# LPC800 register map
File version: 0.2
CPU: CM0 r0p0, little endian, no MPU, no FPU, 2 interrupt priority bits
Registers are 32-bit, read-write, reset 0x0 unless marked. A register's access mark holds for its fields unless they carry their own. Offsets are from the block's base; [hi:lo] are bit positions.

## SWM — Switch matrix (SWM)
Base 0x4000C000
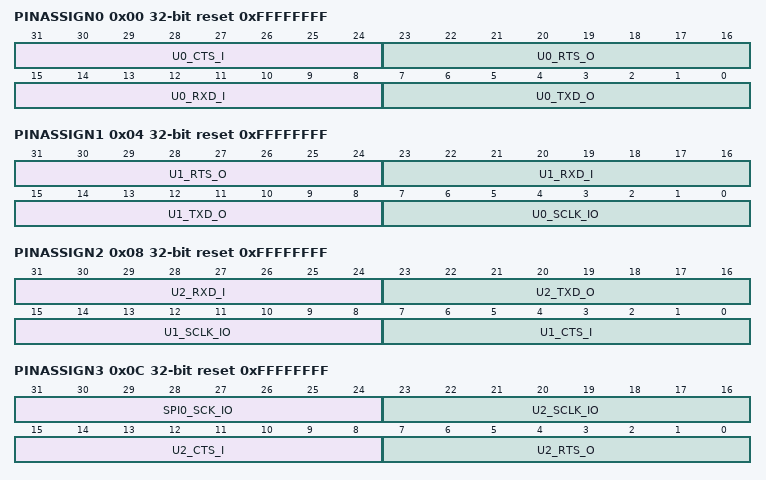
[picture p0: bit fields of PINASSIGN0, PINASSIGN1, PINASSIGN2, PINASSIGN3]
0x00 PINASSIGN0 reset 0xFFFFFFFF — Pin assign register 0. Assign movable functions U0_TXD, U0_RXD, U0_RTS, U0_CTS
  [31:24] U0_CTS_I — U0_CTS function assignment. The value is the pin number to be assigned to this function. The following pins are available: PIO0_0 (= 0) to PIO0_17 (= 0x11).
  [23:16] U0_RTS_O — U0_RTS function assignment. The value is the pin number to be assigned to this function. The following pins are available: PIO0_0 (= 0) to PIO0_17 (= 0x11).
  [15:8] U0_RXD_I — U0_RXD function assignment. The value is the pin number to be assigned to this function. The following pins are available: PIO0_0 (= 0) to PIO0_17 (= 0x11).
  [7:0] U0_TXD_O — U0_TXD function assignment. The value is the pin number to be assigned to this function. The following pins are available: PIO0_0 (= 0) to PIO0_17 (= 0x11).
0x04 PINASSIGN1 reset 0xFFFFFFFF — Pin assign register 1. Assign movable functions U0_SCLC, U1_TXD, U1_RXD
  [31:24] U1_RTS_O — U1_RTS function assignment. The value is the pin number to be assigned to this function. The following pins are available: PIO0_0 (= 0) to PIO0_17 (= 0x11).
  [23:16] U1_RXD_I — U1_RXD function assignment. The value is the pin number to be assigned to this function. The following pins are available: PIO0_0 (= 0) to PIO0_17 (= 0x11).
  [15:8] U1_TXD_O — U1_TXD function assignment. The value is the pin number to be assigned to this function. The following pins are available: PIO0_0 (= 0) to PIO0_17 (= 0x11).
  [7:0] U0_SCLK_IO — U0_SCLK function assignment. The value is the pin number to be assigned to this function. The following pins are available: PIO0_0 (= 0) to PIO0_17 (= 0x11).
0x08 PINASSIGN2 reset 0xFFFFFFFF — Pin assign register 2. Assign movable functions U2_TXD, U2_RXD
  [31:24] U2_RXD_I — U2_RXD function assignment. The value is the pin number to be assigned to this function. The following pins are available: PIO0_0 (= 0) to PIO0_17 (= 0x11).
  [23:16] U2_TXD_O — U2_TXD function assignment. The value is the pin number to be assigned to this function. The following pins are available: PIO0_0 (= 0) to PIO0_17 (= 0x11).
  [15:8] U1_SCLK_IO — U1_SCLK function assignment. The value is the pin number to be assigned to this function. The following pins are available: PIO0_0 (= 0) to PIO0_17 (= 0x11).
  [7:0] U1_CTS_I — U1_CTS function assignment. The value is the pin number to be assigned to this function. The following pins are available: PIO0_0 (= 0) to PIO0_17 (= 0x11).
0x0C PINASSIGN3 reset 0xFFFFFFFF — Pin assignregister 3. Assign movable function SPI0_SCK
  [31:24] SPI0_SCK_IO — SPI0_SCK function assignment. The value is the pin number to be assigned to this function. The following pins are available: PIO0_0 (= 0) to PIO0_17 (= 0x11).
  [23:16] U2_SCLK_IO — U2_SCLK function assignment. The value is the pin number to be assigned to this function. The following pins are available: PIO0_0 (= 0) to PIO0_17 (= 0x11).
  [15:8] U2_CTS_I — U2_CTS function assignment. The value is the pin number to be assigned to this function. The following pins are available: PIO0_0 (= 0) to PIO0_17 (= 0x11).
  [7:0] U2_RTS_O — U2_RTS function assignment. The value is the pin number to be assigned to this function. The following pins are available: PIO0_0 (= 0) to PIO0_17 (= 0x11).
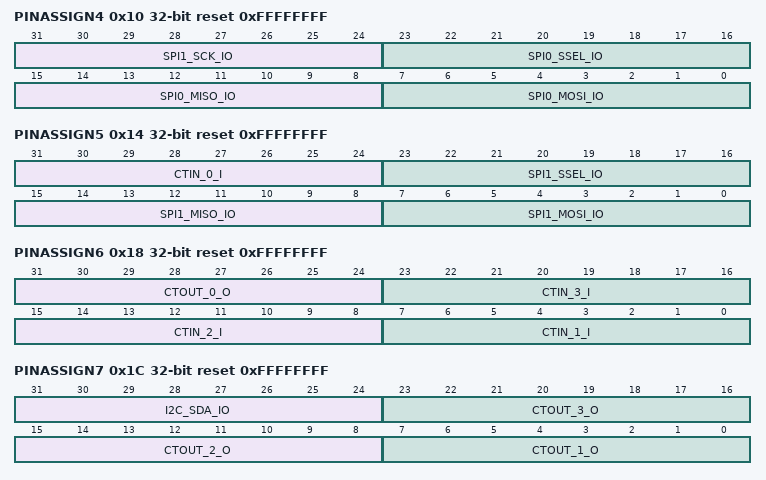
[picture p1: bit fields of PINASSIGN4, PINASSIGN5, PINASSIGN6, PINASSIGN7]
0x10 PINASSIGN4 reset 0xFFFFFFFF — Pin assign register 4. Assign movable functions SPI0_MOSI, SPI0_MISO, SPI0_SSEL, SPI1_SCK
  [31:24] SPI1_SCK_IO — SPI1_SCK function assignment. The value is the pin number to be assigned to this function. The following pins are available: PIO0_0 (= 0) to PIO0_17 (= 0x11).
  [23:16] SPI0_SSEL_IO — SPI0_SSEL function assignment. The value is the pin number to be assigned to this function. The following pins are available: PIO0_0 (= 0) to PIO0_17 (= 0x11).
  [15:8] SPI0_MISO_IO — SPI0_MISIO function assignment. The value is the pin number to be assigned to this function. The following pins are available: PIO0_0 (= 0) to PIO0_17 (= 0x11).
  [7:0] SPI0_MOSI_IO — SPI0_MOSI function assignment. The value is the pin number to be assigned to this function. The following pins are available: PIO0_0 (= 0) to PIO0_17 (= 0x11).
0x14 PINASSIGN5 reset 0xFFFFFFFF — Pin assign register 5. Assign movable functions SPI1_MOSI, SPI1_MISO, SPI1_SSEL, CTIN_0
  [31:24] CTIN_0_I — CTIN_0 function assignment. The value is the pin number to be assigned to this function. The following pins are available: PIO0_0 (= 0) to PIO0_17 (= 0x11).
  [23:16] SPI1_SSEL_IO — SPI1_SSEL function assignment. The value is the pin number to be assigned to this function. The following pins are available: PIO0_0 (= 0) to PIO0_17 (= 0x11).
  [15:8] SPI1_MISO_IO — SPI1_MISIO function assignment. The value is the pin number to be assigned to this function. The following pins are available: PIO0_0 (= 0) to PIO0_17 (= 0x11).
  [7:0] SPI1_MOSI_IO — SPI1_MOSI function assignment. The value is the pin number to be assigned to this function. The following pins are available: PIO0_0 (= 0) to PIO0_17 (= 0x11).
0x18 PINASSIGN6 reset 0xFFFFFFFF — Pin assign register 6. Assign movable functions CTIN_1, CTIN_2, CTIN_3, CTOUT_0
  [31:24] CTOUT_0_O — CTOUT_0 function assignment. The value is the pin number to be assigned to this function. The following pins are available: PIO0_0 (= 0) to PIO0_17 (= 0x11).
  [23:16] CTIN_3_I — CTIN_3 function assignment. The value is the pin number to be assigned to this function. The following pins are available: PIO0_0 (= 0) to PIO0_17 (= 0x11).
  [15:8] CTIN_2_I — CTIN_2function assignment. The value is the pin number to be assigned to this function. The following pins are available: PIO0_0 (= 0) to PIO0_17 (= 0x11).
  [7:0] CTIN_1_I — CTIN_1 function assignment. The value is the pin number to be assigned to this function. The following pins are available: PIO0_0 (= 0) to PIO0_17 (= 0x11).
0x1C PINASSIGN7 reset 0xFFFFFFFF — Pin assign egister 7. Assign movable functions CTOUT_1, CTOUT_2, CTOUT_3, I2C_SDA
  [31:24] I2C_SDA_IO — I2C_SDA function assignment. The value is the pin number to be assigned to this function. The following pins are available: PIO0_0 (= 0) to PIO0_17 (= 0x11).
  [23:16] CTOUT_3_O — CTOUT_3 function assignment. The value is the pin number to be assigned to this function. The following pins are available: PIO0_0 (= 0) to PIO0_17 (= 0x11).
  [15:8] CTOUT_2_O — CTOUT_2 function assignment. The value is the pin number to be assigned to this function. The following pins are available: PIO0_0 (= 0) to PIO0_17 (= 0x11).
  [7:0] CTOUT_1_O — CTOUT_1 function assignment. The value is the pin number to be assigned to this function. The following pins are available: PIO0_0 (= 0) to PIO0_17 (= 0x11).
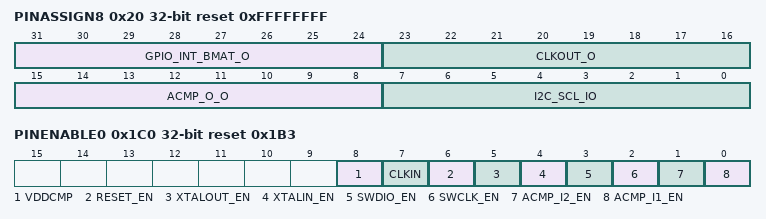
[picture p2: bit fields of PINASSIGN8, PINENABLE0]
0x20 PINASSIGN8 reset 0xFFFFFFFF — Pin assign register 8. Assign movable functions I2C_SCL, ACMP_O, CLKOUT, GPIO_INT_BMAT
  [31:24] GPIO_INT_BMAT_O — GPIO_INT_BMAT function assignment. The value is the pin number to be assigned to this function. The following pins are available: PIO0_0 (= 0) to PIO0_17 (= 0x11).
  [23:16] CLKOUT_O — CLKOUT function assignment. The value is the pin number to be assigned to this function. The following pins are available: PIO0_0 (= 0) to PIO0_17 (= 0x11).
  [15:8] ACMP_O_O — ACMP_O_O function assignment. The value is the pin number to be assigned to this function. The following pins are available: PIO0_0 (= 0) to PIO0_17 (= 0x11).
  [7:0] I2C_SCL_IO — I2C_SCL function assignment. The value is the pin number to be assigned to this function. The following pins are available: PIO0_0 (= 0) to PIO0_17 (= 0x11).
0x1C0 PINENABLE0 reset 0x1B3 — Pin enable register 0. Enables fixed-pin functions ACMP_I0, ACMP_I1, SWCLK, SWDIO, XTALIN, XTALOUT, RESET, CLKIN, VDDCMP
  [8] VDDCMP — Enables fixed-pin function. Writing a 1 deselects the function and any movable function can be assigned to this pin. By default the fixed--pin function is deselected and GPIO is assigned to this pin.
    0=ENABLE_VDDCMP_THIS_ (Enable VDDCMP. This function is enabled on pin PIO0_6.); 1=DISABLE_VDDCMP_GPIO (Disable VDDCMP. GPIO function PIO0_6 (default) or any other movable function can be assigned to pin PIO0_6.)
  [7] CLKIN — Enables fixed-pin function. Writing a 1 deselects the function and any movable function can be assigned to this pin. By default the fixed-pin function is deselected and GPIO is assigned to this pin. Functions CLKIN and ACMP_I2 are connected to the same pin PIO0_1. To use CLKIN, disable ACMP_I2 in bit 1 of this register and enable CLKIN.
    0=ENABLE_CLKIN_THIS_F (Enable CLKIN. This function is enabled on pin PIO0_1.); 1=DISABLE_CLKIN_GPIO_ (Disable CLKIN. GPIO function PIO0_1 (default) or any other movable function can be assigned to pin CLKIN.)
  [6] RESET_EN — Enables fixed-pin function. Writing a 1 deselects the function and any movable function can be assigned to this pin. This function is selected by default.
    0=ENABLE_RESET_THIS_F (Enable RESET. This function is enabled on pin PIO0_5.); 1=DISABLE_RESET_GPIO_ (Disable RESET. GPIO function PIO0_5 is selected on this pin. Any other movable function can be assigned to pin PIO0_5.)
  [5] XTALOUT_EN — Enables fixed-pin function. Writing a 1 deselects the function and any movable function can be assigned to this pin. By default the fixed--pin function is deselected and GPIO is assigned to this pin.
    0=ENABLE_XTALOUT_THIS (Enable XTALOUT. This function is enabled on pin PIO0_9.); 1=DISABLE_XTALOUT_GPI (Disable XTALOUT. GPIO function PIO0_9 (default) or any other movable function can be assigned to pin PIO0_9.)
  [4] XTALIN_EN — Enables fixed-pin function. Writing a 1 deselects the function and any movable function can be assigned to this pin. By default the fixed--pin function is deselected and GPIO is assigned to this pin.
    0=ENABLE_XTALIN_THIS_ (Enable XTALIN. This function is enabled on pin PIO0_8.); 1=DISABLE_XTALIN_GPIO (Disable XTALIN. GPIO function PIO0_8 (default) or any other movable function can be assigned to pin PIO0_8.)
  [3] SWDIO_EN — Enables fixed-pin function. Writing a 1 deselects the function and any movable function can be assigned to this pin. This function is selected by default.
    0=ENABLE_SWDIO_THIS_F (Enable SWDIO. This function is enabled on pin PIO0_2.); 1=DISABLE_SWDIO_GPIO_ (Disable SWDIO. GPIO function PIO0_2 is selected on this pin. Any other movable function can be assigned to pin PIO0_2.)
  [2] SWCLK_EN — Enables fixed-pin function. Writing a 1 deselects the function and any movable function can be assigned to this pin. This function is selected by default.
    0=ENABLE_SWCLK_THIS_F (Enable SWCLK. This function is enabled on pin PIO0_3.); 1=DISABLE_SWCLK_GPIO_ (Disable SWCLK. GPIO function PIO0_3 is selected on this pin. Any other movable function can be assigned to pin PIO0_3.)
  [1] ACMP_I2_EN — Enables fixed-pin function. Writing a 1 deselects the function and any movable function can be assigned to this pin. By default the fixed-pin function is deselected and GPIO is assigned to this pin. Functions CLKIN and ACMP_I2 are connected to the same pin PIO0_1. To use ACMP_I2, disable the CLKIN function in bit 7 of this register and enable ACMP_I2.
    0=ENABLE_ACMP_I2_THIS (Enable ACMP_I2. This function is enabled on pin PIO0_1.); 1=DISABLE_ACMP_I2_GPI (Disable ACMP_I2. GPIO function PIO0_1 (default) or any other movable function can be assigned to pin PIO0_1.)
  [0] ACMP_I1_EN — Enables fixed-pin function. Writing a 1 deselects the function and any movable function can be assigned to this pin. By default the fixed--pin function is deselected and GPIO is assigned to this pin.
    0=ENABLE_ACMP_I1_THIS (Enable ACMP_I1. This function is enabled on pin PIO0_0.); 1=DISABLE_ACMP_I1_GPI (Disable ACMP_I1. GPIO function PIO0_0 (default) or any other movable function can be assigned to pin PIO0_0.)
